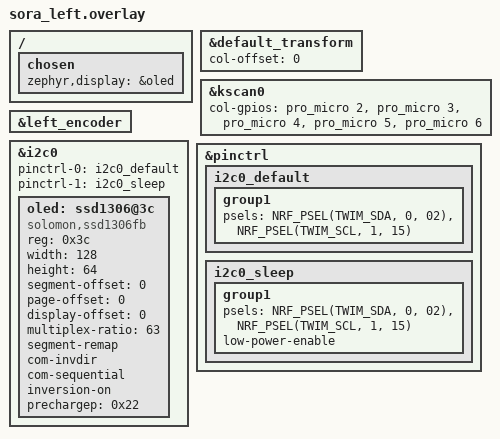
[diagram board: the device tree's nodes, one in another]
#include "sora.dtsi"

/ {
    chosen {
        zephyr,display = &oled;
    };
};

&default_transform {
    col-offset = <0>;
};

&kscan0 {
    status = "okay";
    col-gpios
        = <&pro_micro 2 GPIO_ACTIVE_HIGH>
        , <&pro_micro 3 GPIO_ACTIVE_HIGH>
        , <&pro_micro 4 GPIO_ACTIVE_HIGH>
        , <&pro_micro 5 GPIO_ACTIVE_HIGH>
        , <&pro_micro 6 GPIO_ACTIVE_HIGH>
        ;
};

&left_encoder {
    status = "okay";
};

&i2c0 {
    status = "okay";
    pinctrl-0 = <&i2c0_default>;
    pinctrl-1 = <&i2c0_sleep>;
    pinctrl-names = "default", "sleep";
    //clock-frequency = <I2C_BITRATE_STANDARD>;

    /* Nodes using the bus go here */
    oled: ssd1306@3c {
        compatible = "solomon,ssd1306fb";
        reg = <0x3c>;
        width = <128>;
        height = <64>;
        segment-offset = <0>;
        page-offset = <0>;
        display-offset = <0>;
        multiplex-ratio = <63>;
        segment-remap;
        com-invdir;
        com-sequential;
        inversion-on;
        prechargep = <0x22>;
    };
};

  &pinctrl {
      i2c0_default: i2c0_default {
        group1 {
            psels = <NRF_PSEL(TWIM_SDA, 0, 02)>,
                    <NRF_PSEL(TWIM_SCL, 1, 15)>;
        };
    };

    i2c0_sleep: i2c0_sleep {
        group1 {
            psels = <NRF_PSEL(TWIM_SDA, 0, 02)>,
                    <NRF_PSEL(TWIM_SCL, 1, 15)>;
            low-power-enable;
        };
    };
  };
